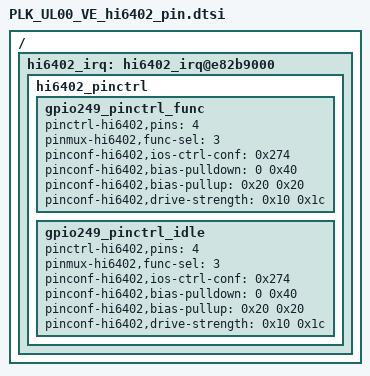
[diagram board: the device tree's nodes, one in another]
/ {
	hi6402_irq: hi6402_irq@e82b9000 {
		hi6402_pinctrl {
			gpio249_pinctrl_func: gpio249_pinctrl_func {
				pinctrl-hi6402,pins = <4>;
				pinmux-hi6402,func-sel = <3>;
				pinconf-hi6402,ios-ctrl-conf = <0x274>;
				pinconf-hi6402,bias-pulldown = <0 0x40>;
				pinconf-hi6402,bias-pullup = <0x20 0x20>;
				pinconf-hi6402,drive-strength = <0x10 0x1c>;
			};
			gpio249_pinctrl_idle: gpio249_pinctrl_idle {
				pinctrl-hi6402,pins = <4>;
				pinmux-hi6402,func-sel = <3>;
				pinconf-hi6402,ios-ctrl-conf = <0x274>;
				pinconf-hi6402,bias-pulldown = <0 0x40>;
				pinconf-hi6402,bias-pullup = <0x20 0x20>;
				pinconf-hi6402,drive-strength = <0x10 0x1c>;
			};

		};

	};

};
